AUTOSAR XML (schema 00046)
package /ComponentTypes
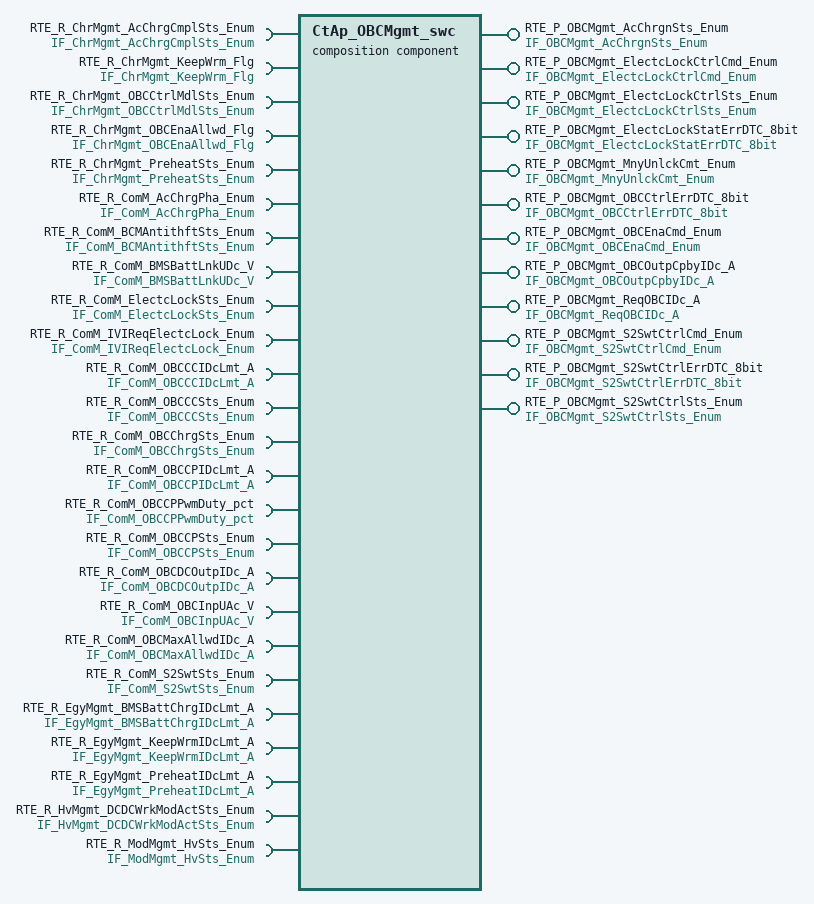
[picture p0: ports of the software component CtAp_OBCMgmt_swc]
  composition sw component type CtAp_OBCMgmt_swc
    12 x provide port:
      RTE_P_OBCMgmt_AcChrgnSts_Enum: nonqueued-sender-com-spec{data-element=tec_OBCMgmt_AcChrgnSts_Enum, init-value=0}, provided-interface=IF_OBCMgmt_AcChrgnSts_Enum
      RTE_P_OBCMgmt_ElectcLockCtrlCmd_Enum: nonqueued-sender-com-spec{data-element=tec_OBCMgmt_ElectcLockCtrlCmd_Enum, init-value=0}, provided-interface=IF_OBCMgmt_ElectcLockCtrlCmd_Enum
      RTE_P_OBCMgmt_ElectcLockCtrlSts_Enum: nonqueued-sender-com-spec{data-element=tec_OBCMgmt_ElectcLockCtrlSts_Enum, init-value=0}, provided-interface=IF_OBCMgmt_ElectcLockCtrlSts_Enum
      RTE_P_OBCMgmt_ElectcLockStatErrDTC_8bit: nonqueued-sender-com-spec{data-element=tec_OBCMgmt_ElectcLockStatErrDTC_8bit, init-value=0}, provided-interface=IF_OBCMgmt_ElectcLockStatErrDTC_8bit
      RTE_P_OBCMgmt_MnyUnlckCmt_Enum: nonqueued-sender-com-spec{data-element=tec_OBCMgmt_MnyUnlckCmt_Enum, init-value=0}, provided-interface=IF_OBCMgmt_MnyUnlckCmt_Enum
      RTE_P_OBCMgmt_OBCCtrlErrDTC_8bit: nonqueued-sender-com-spec{data-element=tec_OBCMgmt_OBCCtrlErrDTC_8bit, init-value=0}, provided-interface=IF_OBCMgmt_OBCCtrlErrDTC_8bit
      RTE_P_OBCMgmt_OBCEnaCmd_Enum: nonqueued-sender-com-spec{data-element=tec_OBCMgmt_OBCEnaCmd_Enum, init-value=0}, provided-interface=IF_OBCMgmt_OBCEnaCmd_Enum
      RTE_P_OBCMgmt_OBCOutpCpbyIDc_A: nonqueued-sender-com-spec{data-element=tec_OBCMgmt_OBCOutpCpbyIDc_A, init-value=0}, provided-interface=IF_OBCMgmt_OBCOutpCpbyIDc_A
      RTE_P_OBCMgmt_ReqOBCIDc_A: nonqueued-sender-com-spec{data-element=tec_OBCMgmt_ReqOBCIDc_A, init-value=0}, provided-interface=IF_OBCMgmt_ReqOBCIDc_A
      RTE_P_OBCMgmt_S2SwtCtrlCmd_Enum: nonqueued-sender-com-spec{data-element=tec_OBCMgmt_S2SwtCtrlCmd_Enum, init-value=0}, provided-interface=IF_OBCMgmt_S2SwtCtrlCmd_Enum
      RTE_P_OBCMgmt_S2SwtCtrlErrDTC_8bit: nonqueued-sender-com-spec{data-element=tec_OBCMgmt_S2SwtCtrlErrDTC_8bit, init-value=0}, provided-interface=IF_OBCMgmt_S2SwtCtrlErrDTC_8bit
      RTE_P_OBCMgmt_S2SwtCtrlSts_Enum: nonqueued-sender-com-spec{data-element=tec_OBCMgmt_S2SwtCtrlSts_Enum, init-value=0}, provided-interface=IF_OBCMgmt_S2SwtCtrlSts_Enum
    25 x require port:
      RTE_R_ChrMgmt_AcChrgCmplSts_Enum: nonqueued-receiver-com-spec{data-element=tec_ChrMgmt_AcChrgCmplSts_Enum, filter=data-filter-type=ALWAYS, init-value=0}, required-interface=IF_ChrMgmt_AcChrgCmplSts_Enum
      RTE_R_ChrMgmt_KeepWrm_Flg: nonqueued-receiver-com-spec{data-element=tec_ChrMgmt_KeepWrm_Flg, filter=data-filter-type=ALWAYS, init-value=0}, required-interface=IF_ChrMgmt_KeepWrm_Flg
      RTE_R_ChrMgmt_OBCCtrlMdlSts_Enum: nonqueued-receiver-com-spec{data-element=tec_ChrMgmt_OBCCtrlMdlSts_Enum, filter=data-filter-type=ALWAYS, init-value=0}, required-interface=IF_ChrMgmt_OBCCtrlMdlSts_Enum
      RTE_R_ChrMgmt_OBCEnaAllwd_Flg: nonqueued-receiver-com-spec{data-element=tec_ChrMgmt_OBCEnaAllwd_Flg, filter=data-filter-type=ALWAYS, init-value=0}, required-interface=IF_ChrMgmt_OBCEnaAllwd_Flg
      RTE_R_ChrMgmt_PreheatSts_Enum: nonqueued-receiver-com-spec{data-element=tec_ChrMgmt_PreheatSts_Enum, filter=data-filter-type=ALWAYS, init-value=0}, required-interface=IF_ChrMgmt_PreheatSts_Enum
      RTE_R_ComM_AcChrgPha_Enum: nonqueued-receiver-com-spec{data-element=tec_ComM_AcChrgPha_Enum, filter=data-filter-type=ALWAYS, init-value=0}, required-interface=IF_ComM_AcChrgPha_Enum
      RTE_R_ComM_BCMAntithftSts_Enum: nonqueued-receiver-com-spec{data-element=tec_ComM_BCMAntithftSts_Enum, filter=data-filter-type=ALWAYS, init-value=0}, required-interface=IF_ComM_BCMAntithftSts_Enum
      RTE_R_ComM_BMSBattLnkUDc_V: nonqueued-receiver-com-spec{data-element=tec_ComM_BMSBattLnkUDc_V, filter=data-filter-type=ALWAYS, init-value=0}, required-interface=IF_ComM_BMSBattLnkUDc_V
      RTE_R_ComM_ElectcLockSts_Enum: nonqueued-receiver-com-spec{data-element=tec_ComM_ElectcLockSts_Enum, filter=data-filter-type=ALWAYS, init-value=0}, required-interface=IF_ComM_ElectcLockSts_Enum
      RTE_R_ComM_IVIReqElectcLock_Enum: nonqueued-receiver-com-spec{data-element=tec_ComM_IVIReqElectcLock_Enum, filter=data-filter-type=ALWAYS, init-value=0}, required-interface=IF_ComM_IVIReqElectcLock_Enum
      RTE_R_ComM_OBCCCIDcLmt_A: nonqueued-receiver-com-spec{data-element=tec_ComM_OBCCCIDcLmt_A, filter=data-filter-type=ALWAYS, init-value=0}, required-interface=IF_ComM_OBCCCIDcLmt_A
      RTE_R_ComM_OBCCCSts_Enum: nonqueued-receiver-com-spec{data-element=tec_ComM_OBCCCSts_Enum, filter=data-filter-type=ALWAYS, init-value=0}, required-interface=IF_ComM_OBCCCSts_Enum
      RTE_R_ComM_OBCChrgSts_Enum: nonqueued-receiver-com-spec{data-element=tec_ComM_OBCChrgSts_Enum, filter=data-filter-type=ALWAYS, init-value=0}, required-interface=IF_ComM_OBCChrgSts_Enum
      RTE_R_ComM_OBCCPIDcLmt_A: nonqueued-receiver-com-spec{data-element=tec_ComM_OBCCPIDcLmt_A, filter=data-filter-type=ALWAYS, init-value=0}, required-interface=IF_ComM_OBCCPIDcLmt_A
      RTE_R_ComM_OBCCPPwmDuty_pct: nonqueued-receiver-com-spec{data-element=tec_ComM_OBCCPPwmDuty_pct, filter=data-filter-type=ALWAYS, init-value=0}, required-interface=IF_ComM_OBCCPPwmDuty_pct
      RTE_R_ComM_OBCCPSts_Enum: nonqueued-receiver-com-spec{data-element=tec_ComM_OBCCPSts_Enum, filter=data-filter-type=ALWAYS, init-value=0}, required-interface=IF_ComM_OBCCPSts_Enum
      RTE_R_ComM_OBCDCOutpIDc_A: nonqueued-receiver-com-spec{data-element=tec_ComM_OBCDCOutpIDc_A, filter=data-filter-type=ALWAYS, init-value=0}, required-interface=IF_ComM_OBCDCOutpIDc_A
      RTE_R_ComM_OBCInpUAc_V: nonqueued-receiver-com-spec{data-element=tec_ComM_OBCInpUAc_V, filter=data-filter-type=ALWAYS, init-value=0}, required-interface=IF_ComM_OBCInpUAc_V
      RTE_R_ComM_OBCMaxAllwdIDc_A: nonqueued-receiver-com-spec{data-element=tec_ComM_OBCMaxAllwdIDc_A, filter=data-filter-type=ALWAYS, init-value=0}, required-interface=IF_ComM_OBCMaxAllwdIDc_A
      RTE_R_ComM_S2SwtSts_Enum: nonqueued-receiver-com-spec{data-element=tec_ComM_S2SwtSts_Enum, filter=data-filter-type=ALWAYS, init-value=0}, required-interface=IF_ComM_S2SwtSts_Enum
      RTE_R_EgyMgmt_BMSBattChrgIDcLmt_A: nonqueued-receiver-com-spec{data-element=tec_EgyMgmt_BMSBattChrgIDcLmt_A, filter=data-filter-type=ALWAYS, init-value=0}, required-interface=IF_EgyMgmt_BMSBattChrgIDcLmt_A
      RTE_R_EgyMgmt_KeepWrmIDcLmt_A: nonqueued-receiver-com-spec{data-element=tec_EgyMgmt_KeepWrmIDcLmt_A, filter=data-filter-type=ALWAYS, init-value=0}, required-interface=IF_EgyMgmt_KeepWrmIDcLmt_A
      RTE_R_EgyMgmt_PreheatIDcLmt_A: nonqueued-receiver-com-spec{data-element=tec_EgyMgmt_PreheatIDcLmt_A, filter=data-filter-type=ALWAYS, init-value=0}, required-interface=IF_EgyMgmt_PreheatIDcLmt_A
      RTE_R_HvMgmt_DCDCWrkModActSts_Enum: nonqueued-receiver-com-spec{data-element=tec_HvMgmt_DCDCWrkModActSts_Enum, filter=data-filter-type=ALWAYS, init-value=0}, required-interface=IF_HvMgmt_DCDCWrkModActSts_Enum
      RTE_R_ModMgmt_HvSts_Enum: nonqueued-receiver-com-spec{data-element=tec_ModMgmt_HvSts_Enum, filter=data-filter-type=ALWAYS, init-value=0}, required-interface=IF_ModMgmt_HvSts_Enum
    4 x component:
      CtAp_ACParMgmt: type=CtAp_ACParMgmt
      CtAp_EmMgmt: type=CtAp_EmMgmt
      CtAp_OBCStsMgmt: type=CtAp_OBCStsMgmt
      CtAp_S2Mgmt: type=CtAp_S2Mgmt
    connect CtAp_EmMgmt.RTE_P_OBCMgmt_ElectcLockCtrlSts_Enum -> CtAp_OBCStsMgmt.RTE_R_OBCMgmt_ElectcLockCtrlSts_Enum
    connect CtAp_EmMgmt.RTE_P_OBCMgmt_ElectcLockCtrlSts_Enum -> CtAp_S2Mgmt.RTE_R_OBCMgmt_ElectcLockCtrlSts_Enum
    connect CtAp_OBCStsMgmt.RTE_P_OBCMgmt_AcChrgnSts_Enum -> CtAp_ACParMgmt.RTE_R_OBCMgmt_AcChrgnSts_Enum
    connect CtAp_OBCStsMgmt.RTE_P_OBCMgmt_AcChrgnSts_Enum -> CtAp_EmMgmt.RTE_R_OBCMgmt_AcChrgnSts_Enum
    connect CtAp_OBCStsMgmt.RTE_P_OBCMgmt_AcChrgnSts_Enum -> CtAp_S2Mgmt.RTE_R_OBCMgmt_AcChrgnSts_Enum
    connect CtAp_S2Mgmt.RTE_P_OBCMgmt_S2SwtCtrlSts_Enum -> CtAp_EmMgmt.RTE_R_OBCMgmt_S2SwtCtrlSts_Enum
    delegate CtAp_OBCStsMgmt.RTE_P_OBCMgmt_AcChrgnSts_Enum <-> outer port RTE_P_OBCMgmt_AcChrgnSts_Enum
    delegate CtAp_EmMgmt.RTE_P_OBCMgmt_ElectcLockCtrlCmd_Enum <-> outer port RTE_P_OBCMgmt_ElectcLockCtrlCmd_Enum
    delegate CtAp_EmMgmt.RTE_P_OBCMgmt_ElectcLockCtrlSts_Enum <-> outer port RTE_P_OBCMgmt_ElectcLockCtrlSts_Enum
    delegate CtAp_EmMgmt.RTE_P_OBCMgmt_ElectcLockStatErrDTC_8bit <-> outer port RTE_P_OBCMgmt_ElectcLockStatErrDTC_8bit
    delegate CtAp_EmMgmt.RTE_P_OBCMgmt_MnyUnlckCmt_Enum <-> outer port RTE_P_OBCMgmt_MnyUnlckCmt_Enum
    delegate CtAp_OBCStsMgmt.RTE_P_OBCMgmt_OBCCtrlErrDTC_8bit <-> outer port RTE_P_OBCMgmt_OBCCtrlErrDTC_8bit
    delegate CtAp_OBCStsMgmt.RTE_P_OBCMgmt_OBCEnaCmd_Enum <-> outer port RTE_P_OBCMgmt_OBCEnaCmd_Enum
    delegate CtAp_ACParMgmt.RTE_P_OBCMgmt_OBCOutpCpbyIDc_A <-> outer port RTE_P_OBCMgmt_OBCOutpCpbyIDc_A
    delegate CtAp_ACParMgmt.RTE_P_OBCMgmt_ReqOBCIDc_A <-> outer port RTE_P_OBCMgmt_ReqOBCIDc_A
    delegate CtAp_S2Mgmt.RTE_P_OBCMgmt_S2SwtCtrlCmd_Enum <-> outer port RTE_P_OBCMgmt_S2SwtCtrlCmd_Enum
    delegate CtAp_S2Mgmt.RTE_P_OBCMgmt_S2SwtCtrlErrDTC_8bit <-> outer port RTE_P_OBCMgmt_S2SwtCtrlErrDTC_8bit
    delegate CtAp_S2Mgmt.RTE_P_OBCMgmt_S2SwtCtrlSts_Enum <-> outer port RTE_P_OBCMgmt_S2SwtCtrlSts_Enum
    delegate CtAp_OBCStsMgmt.RTE_R_ChrMgmt_AcChrgCmplSts_Enum <-> outer port RTE_R_ChrMgmt_AcChrgCmplSts_Enum
    delegate CtAp_OBCStsMgmt.RTE_R_ChrMgmt_KeepWrm_Flg <-> outer port RTE_R_ChrMgmt_KeepWrm_Flg
    delegate CtAp_OBCStsMgmt.RTE_R_ChrMgmt_OBCCtrlMdlSts_Enum <-> outer port RTE_R_ChrMgmt_OBCCtrlMdlSts_Enum
    delegate CtAp_OBCStsMgmt.RTE_R_ChrMgmt_OBCEnaAllwd_Flg <-> outer port RTE_R_ChrMgmt_OBCEnaAllwd_Flg
    delegate CtAp_OBCStsMgmt.RTE_R_ChrMgmt_PreheatSts_Enum <-> outer port RTE_R_ChrMgmt_PreheatSts_Enum
    delegate CtAp_ACParMgmt.RTE_R_ComM_AcChrgPha_Enum <-> outer port RTE_R_ComM_AcChrgPha_Enum
    delegate CtAp_EmMgmt.RTE_R_ComM_BCMAntithftSts_Enum <-> outer port RTE_R_ComM_BCMAntithftSts_Enum
    delegate CtAp_ACParMgmt.RTE_R_ComM_BMSBattLnkUDc_V <-> outer port RTE_R_ComM_BMSBattLnkUDc_V
    delegate CtAp_EmMgmt.RTE_R_ComM_ElectcLockSts_Enum <-> outer port RTE_R_ComM_ElectcLockSts_Enum
    delegate CtAp_EmMgmt.RTE_R_ComM_IVIReqElectcLock_Enum <-> outer port RTE_R_ComM_IVIReqElectcLock_Enum
    delegate CtAp_ACParMgmt.RTE_R_ComM_OBCCCIDcLmt_A <-> outer port RTE_R_ComM_OBCCCIDcLmt_A
    delegate CtAp_EmMgmt.RTE_R_ComM_OBCCCSts_Enum <-> outer port RTE_R_ComM_OBCCCSts_Enum
    delegate CtAp_OBCStsMgmt.RTE_R_ComM_OBCChrgSts_Enum <-> outer port RTE_R_ComM_OBCChrgSts_Enum
    delegate CtAp_ACParMgmt.RTE_R_ComM_OBCCPIDcLmt_A <-> outer port RTE_R_ComM_OBCCPIDcLmt_A
    delegate CtAp_OBCStsMgmt.RTE_R_ComM_OBCCPPwmDuty_pct <-> outer port RTE_R_ComM_OBCCPPwmDuty_pct
    delegate CtAp_EmMgmt.RTE_R_ComM_OBCCPSts_Enum <-> outer port RTE_R_ComM_OBCCPSts_Enum
    delegate CtAp_OBCStsMgmt.RTE_R_ComM_OBCCPSts_Enum <-> outer port RTE_R_ComM_OBCCPSts_Enum
    delegate CtAp_S2Mgmt.RTE_R_ComM_OBCCPSts_Enum <-> outer port RTE_R_ComM_OBCCPSts_Enum
    delegate CtAp_ACParMgmt.RTE_R_ComM_OBCDCOutpIDc_A <-> outer port RTE_R_ComM_OBCDCOutpIDc_A
    delegate CtAp_ACParMgmt.RTE_R_ComM_OBCInpUAc_V <-> outer port RTE_R_ComM_OBCInpUAc_V
    delegate CtAp_S2Mgmt.RTE_R_ComM_OBCInpUAc_V <-> outer port RTE_R_ComM_OBCInpUAc_V
    delegate CtAp_ACParMgmt.RTE_R_ComM_OBCMaxAllwdIDc_A <-> outer port RTE_R_ComM_OBCMaxAllwdIDc_A
    delegate CtAp_S2Mgmt.RTE_R_ComM_S2SwtSts_Enum <-> outer port RTE_R_ComM_S2SwtSts_Enum
    delegate CtAp_ACParMgmt.RTE_R_EgyMgmt_BMSBattChrgIDcLmt_A <-> outer port RTE_R_EgyMgmt_BMSBattChrgIDcLmt_A
    delegate CtAp_ACParMgmt.RTE_R_EgyMgmt_KeepWrmIDcLmt_A <-> outer port RTE_R_EgyMgmt_KeepWrmIDcLmt_A
    delegate CtAp_ACParMgmt.RTE_R_EgyMgmt_PreheatIDcLmt_A <-> outer port RTE_R_EgyMgmt_PreheatIDcLmt_A
    delegate CtAp_ACParMgmt.RTE_R_HvMgmt_DCDCWrkModActSts_Enum <-> outer port RTE_R_HvMgmt_DCDCWrkModActSts_Enum
    delegate CtAp_ACParMgmt.RTE_R_ModMgmt_HvSts_Enum <-> outer port RTE_R_ModMgmt_HvSts_Enum
